# R7FA2L1AB register map
Vendor: Renesas Electronics Corporation; Series: RA2L1; File version: 1.30.00
CPU: CM23 r1p0, little endian, MPU, no FPU, VTOR, 2 interrupt priority bits, 32 interrupts
Registers are 8-bit, read-write, reset 0x0 unless marked. A register's access mark holds for its fields unless they carry their own. Offsets are from the block's base; [hi:lo] are bit positions; {n}, {i} and the like mark numbered series.

## FLCN — Flash I/O Registers
Base 0x407EC000
0x90 DFLCTL — Data Flash Control Register
  [0] DFLEN — Data Flash Access Enable
    0=Access to the data flash is disabled; 1=Access to the data flash is enabled
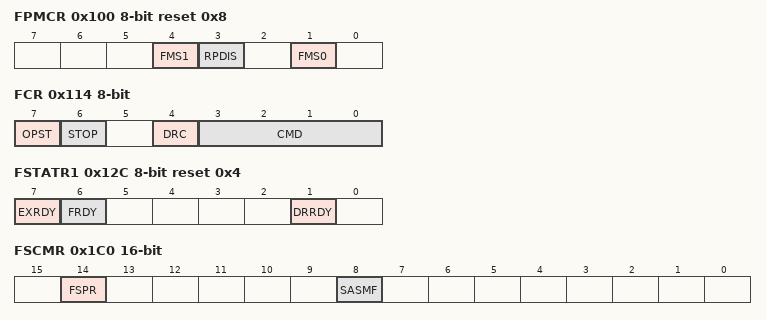
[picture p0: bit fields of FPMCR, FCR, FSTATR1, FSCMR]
0x100 FPMCR reset 0x8 — Flash P/E Mode Control Register
  [4] FMS1 — Flash Operating Mode Select 1
  [3] RPDIS — Code Flash P/E Disable
    0=Programming of the code flash is enabled; 1=Programming of the code flash is disabled
  [1] FMS0 — Flash Operating Mode Select 0
    0=FMS1 = 0: Read mode FMS1 = 1: Data flash P/E mode; 1=FMS1 = 0: Code flash P/E mode FMS1 = 1: Setting prohibited
0x104 FASR — Flash Area Select Register
  [0] EXS — Extra Area Select
    0=User area or data area; 1=Extra area
0x108 FSARL 16-bit — Flash Processing Start Address Register L
  [15:0] FSARL — Flash Processing Start Address L
0x110 FSARH 16-bit — Flash Processing Start Address Register H
  [15:0] FSARH — Flash Processing Start Address H
0x114 FCR — Flash Control Register
  [7] OPST — Processing Start
    0=Processing stops; 1=Processing starts
  [6] STOP — Forced Processing Stop
  [4] DRC — Data Read Completion
    0=Data is not read or next data is requested; 1=Data reading is complete
  [3:0] CMD — Software Command Setting
    1=Program; 3=Blank check (code flash); 4=Block erase; 5=Consecutive read; 6=Chip erase; 11=Blank check (data flash); other=Others (Setting prohibited.)
0x118 FEARL 16-bit — Flash Processing End Address Register L
  [15:0] FEARL — Flash Processing End Address L
0x120 FEARH 16-bit — Flash Processing End Address Register H
  [15:0] FEARH — Flash Processing End Address H
0x124 FRESETR — Flash Reset Register
  [0] FRESET — Software reset of the registers
    0=The registers related to the flash programming are not reset; 1=The registers related to the flash programming are reset
0x12C FSTATR1 ro reset 0x4 — Flash Status Register 1
  [7] EXRDY — Extra Area Ready Flag
    0=The software command of the FEXCR register is not terminated; 1=The software command of the FEXCR register is terminated
  [6] FRDY — Flash Ready Flag
    0=The software command of the FCR register is not terminated; 1=The software command of the FCR register is terminated
  [1] DRRDY — Data Read Ready Flag
    0=The read processing of the consecutive read command at each address is not terminated; 1=The read processing of the consecutive read command at each address is terminated and read data is stored to the FRBH and FRBL registers
0x130 FWBL0 16-bit — Flash Write Buffer Register L0
  [15:0] WDATA — Flash Write Buffer L0
0x138 FWBH0 16-bit — Flash Write Buffer Register H0
  [15:0] WDATA — Flash Write Buffer H0
0x180 FPR reset not defined — Protection Unlock Register
  [7:0] FPR — Protection Unlock
0x184 FPSR ro — Protection Unlock Status Register
  [0] PERR — Protect Error Flag
    0=No error; 1=An error occurs
0x188 FRBL0 16-bit ro — Flash Read Buffer Register L0
  [15:0] RDATA — Flash Read Buffer L0
0x190 FRBH0 16-bit ro — Flash Read Buffer Register H0
  [15:0] RDATA — Flash Read Buffer H0
0x1C0 FSCMR 16-bit ro (reset mask 0xB8FF) — Flash Start-Up Setting Monitor Register
  [14] FSPR — Access Window Protection Flag
    0=Access window setting disabled; 1=Access window setting enabled
  [8] SASMF — Startup Area Setting Monitor Flag
    0=Setting to start up using the alternative area; 1=Setting to start up using the default area
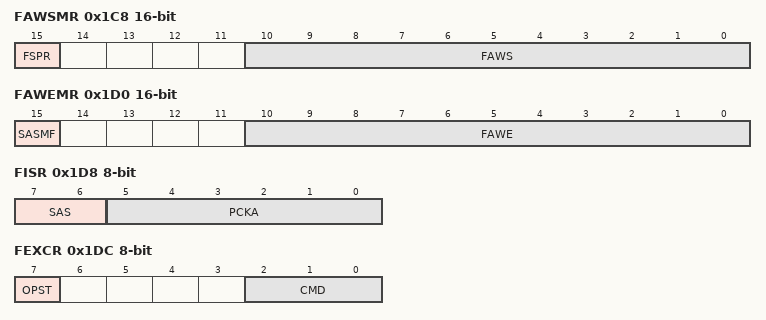
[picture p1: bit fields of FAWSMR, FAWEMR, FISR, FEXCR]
0x1C8 FAWSMR 16-bit ro (reset mask 0xF800) — Flash Access Window Start Address Monitor Register
  [15] FSPR — Access Window Protection Flag
  [10:0] FAWS — Access Window Start Address
0x1D0 FAWEMR 16-bit ro (reset mask 0xF800) — Flash Access Window End Address Monitor Register
  [15] SASMF — Startup Area Setting Monitor Flag
  [10:0] FAWE — Access Window End Address
0x1D8 FISR — Flash Initial Setting Register
  [7:6] SAS — Startup Area Select
    2=The startup area is switched to the default area temporarily; 3=The startup area is switched to the alternate area temporarily; other=Others (The startup area is selected according to the settings of the extra area.)
  [5:0] PCKA — Flash-IF Clock Notification
0x1DC FEXCR — Flash Extra Area Control Register
  [7] OPST — Processing Start
    0=Processing stops; 1=Processing starts
  [2:0] CMD — Software Command Setting
    2=Access window information program Startup area selection and security setting; {v}=OCDID{v-2} program (v=3..6); other=Others (Setting prohibited.)
0x1E0 FEAML 16-bit — Flash Error Address Monitor Register L
0x1E8 FEAMH 16-bit — Flash Error Address Monitor Register H
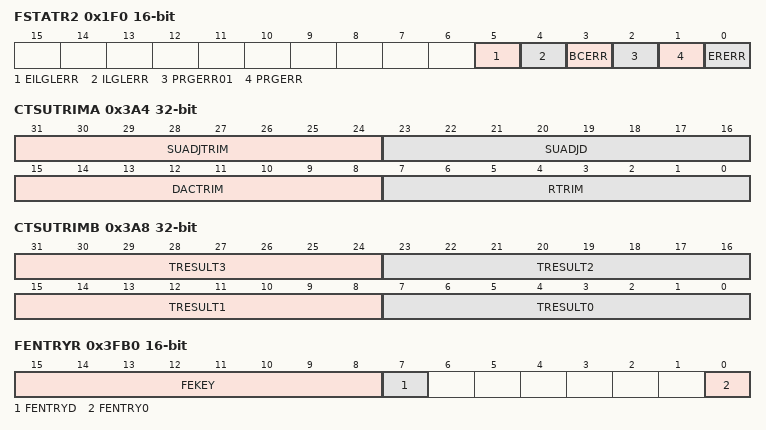
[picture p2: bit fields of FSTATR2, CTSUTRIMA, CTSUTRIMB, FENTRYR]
0x1F0 FSTATR2 16-bit ro — Flash Status Register 2
  [5] EILGLERR — Extra Area Illegal Command Error Flag
    0=No illegal command or illegal access to the extra area is detected; 1=An illegal command or illegal access to the extra area is detected
  [4] ILGLERR — Illegal Command Error Flag
    0=No illegal software command or illegal access is detected; 1=An illegal command or illegal access is detected
  [3] BCERR — Blank Check Error Flag
    0=Blank checking terminates normally; 1=An error occurs during blank checking
  [2] PRGERR01 — Program Error Flag 01
    0=Programming by the FEXCR register terminates normally; 1=An error occurs during programming
  [1] PRGERR — Program Error Flag
    0=Programming terminates normally; 1=An error occurs during programming
  [0] ERERR — Erase Error Flag
    0=Erasure terminates normally; 1=An error occurs during erasure
0x228 TSCDR 32-bit ro reset not defined — Temperature Sensor Calibration Data Register
  [15:0] TSCDR — Temperature Sensor Calibration Data
0x3A4 CTSUTRIMA 32-bit reset not defined — CTSU Trimming Register A
  [31:24] SUADJTRIM — Coefficient of variation for the reference load resistance
  [23:16] SUADJD — CTSU SUCLK Frequency Adjustment
  [15:8] DACTRIM — Linearity Adjustment of Offset Current
  [7:0] RTRIM — CTSU Reference Resistance Adjustment
0x3A8 CTSUTRIMB 32-bit reset not defined — CTSU Trimming Register B
  [31:24] TRESULT3 — The coefficient of variation for the 60 kΩ reference load resistance is stored.
  [23:16] TRESULT2 — The coefficient of variation for the 30 kΩ reference load resistance is stored.
  [15:8] TRESULT1 — The coefficient of variation for the 15 kΩ reference load resistance is stored.
  [7:0] TRESULT0 — The coefficient of variation for the 7.5 kΩ reference load resistance is stored.
0x3FB0 FENTRYR 16-bit — Flash P/E Mode Entry Register
  [15:8] FEKEY wo — Key Code
  [7] FENTRYD — Data Flash P/E Mode Entry
    0=The data flash is the read mode; 1=The data flash is the P/E mode
  [0] FENTRY0 — Code Flash P/E Mode Entry 0
    0=The code flash is the read mode; 1=The code flash is the P/E mode
0x3FC4 FLDWAITR — Memory Wait Cycle Control Register for Data Flash
  [0] FLDWAIT1 — Memory Wait Cycle Select for Data Flash
    0=1 wait access (Default); 1=2 wait access
0x3FC8 PFBER — Prefetch Buffer Enable Register
  [0] PFBE — Prefetch Buffer Enable bit
    0=Prefetch buffer is disabled; 1=Prefetch buffer is enabled
